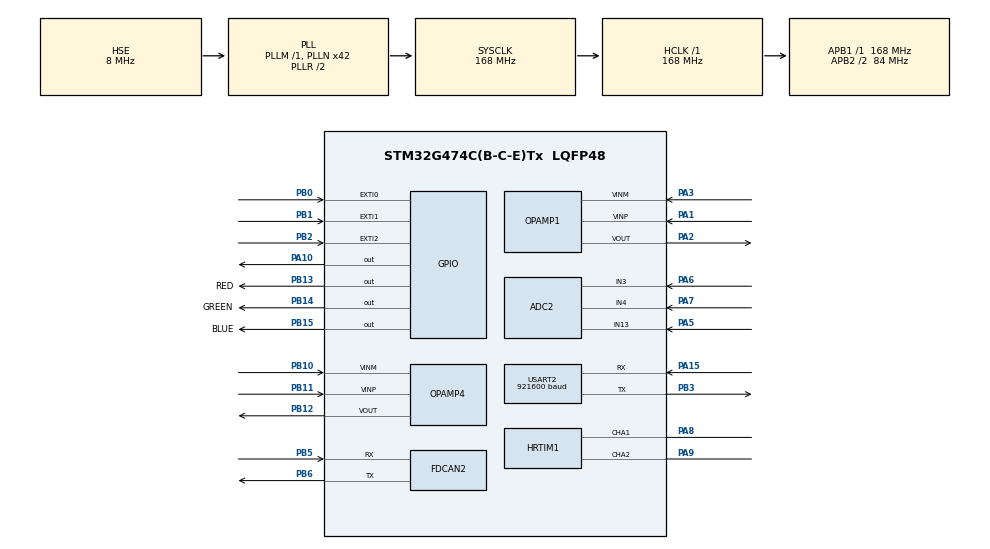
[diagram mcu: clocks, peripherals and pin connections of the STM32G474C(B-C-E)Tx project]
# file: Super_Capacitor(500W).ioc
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ADC1.Channel-1\#ChannelRegularConversion=ADC_CHANNEL_VREFINT
ADC1.Channel-2\#ChannelRegularConversion=ADC_CHANNEL_3
ADC1.Channel-4\#ChannelRegularConversion=ADC_CHANNEL_11
ADC1.DMAAccessModeView=ENABLE
ADC1.DMAContinuousRequests=ENABLE
ADC1.ExternalTrigConv=ADC_EXTERNALTRIG_HRTIM_TRG1
ADC1.Mode=ADC_DUALMODE_REGSIMULT
ADC1.NbrOfConversion=3
ADC1.NbrOfConversionFlag=1
ADC1.OffsetNumber-1\#ChannelRegularConversion=ADC_OFFSET_NONE
ADC1.OffsetNumber-2\#ChannelRegularConversion=ADC_OFFSET_NONE
ADC1.OffsetNumber-4\#ChannelRegularConversion=ADC_OFFSET_NONE
ADC1.OversamplingMode=DISABLE
ADC1.Rank-1\#ChannelRegularConversion=1
ADC1.Rank-2\#ChannelRegularConversion=2
ADC1.Rank-4\#ChannelRegularConversion=3
ADC1.SamplingTime-1\#ChannelRegularConversion=ADC_SAMPLETIME_47CYCLES_5
ADC1.SamplingTime-2\#ChannelRegularConversion=ADC_SAMPLETIME_47CYCLES_5
ADC1.SamplingTime-4\#ChannelRegularConversion=ADC_SAMPLETIME_47CYCLES_5
ADC1.master=1
ADC2.Channel-1\#ChannelRegularConversion=ADC_CHANNEL_3
ADC2.Channel-2\#ChannelRegularConversion=ADC_CHANNEL_4
ADC2.Channel-3\#ChannelRegularConversion=ADC_CHANNEL_13
ADC2.DMAAccessModeView=ENABLE
ADC2.DMAContinuousRequests=DISABLE
ADC2.Mode=ADC_DUALMODE_REGSIMULT
ADC2.NbrOfConversion=3
ADC2.NbrOfConversionFlag=1
ADC2.OffsetNumber-1\#ChannelRegularConversion=ADC_OFFSET_NONE
ADC2.OffsetNumber-2\#ChannelRegularConversion=ADC_OFFSET_NONE
ADC2.OffsetNumber-3\#ChannelRegularConversion=ADC_OFFSET_NONE
ADC2.Overrun=ADC_OVR_DATA_PRESERVED
ADC2.OversamplingMode=DISABLE
ADC2.Rank-1\#ChannelRegularConversion=1
ADC2.Rank-2\#ChannelRegularConversion=2
ADC2.Rank-3\#ChannelRegularConversion=3
ADC2.SamplingTime-1\#ChannelRegularConversion=ADC_SAMPLETIME_47CYCLES_5
ADC2.SamplingTime-2\#ChannelRegularConversion=ADC_SAMPLETIME_47CYCLES_5
ADC2.SamplingTime-3\#ChannelRegularConversion=ADC_SAMPLETIME_47CYCLES_5
Dma.ADC1.2.Direction=DMA_PERIPH_TO_MEMORY
Dma.ADC1.2.EventEnable=DISABLE
Dma.ADC1.2.Instance=DMA1_Channel3
Dma.ADC1.2.MemDataAlignment=DMA_MDATAALIGN_WORD
Dma.ADC1.2.MemInc=DMA_MINC_ENABLE
Dma.ADC1.2.Mode=DMA_CIRCULAR
Dma.ADC1.2.PeriphDataAlignment=DMA_PDATAALIGN_WORD
Dma.ADC1.2.PeriphInc=DMA_PINC_DISABLE
Dma.ADC1.2.Polarity=HAL_DMAMUX_REQ_GEN_RISING
Dma.ADC1.2.Priority=DMA_PRIORITY_VERY_HIGH
Dma.ADC1.2.RequestNumber=1
Dma.ADC1.2.SignalID=NONE
Dma.ADC1.2.SyncEnable=DISABLE
Dma.ADC1.2.SyncPolarity=HAL_DMAMUX_SYNC_NO_EVENT
Dma.ADC1.2.SyncRequestNumber=1
Dma.ADC1.2.SyncSignalID=NONE
Dma.Request0=USART2_RX
Dma.Request1=USART2_TX
Dma.Request2=ADC1
Dma.USART2_RX.0.Direction=DMA_PERIPH_TO_MEMORY
Dma.USART2_RX.0.EventEnable=DISABLE
Dma.USART2_RX.0.Instance=DMA1_Channel1
Dma.USART2_RX.0.MemDataAlignment=DMA_MDATAALIGN_BYTE
Dma.USART2_RX.0.MemInc=DMA_MINC_ENABLE
Dma.USART2_RX.0.Mode=DMA_NORMAL
Dma.USART2_RX.0.PeriphDataAlignment=DMA_PDATAALIGN_BYTE
Dma.USART2_RX.0.PeriphInc=DMA_PINC_DISABLE
Dma.USART2_RX.0.Polarity=HAL_DMAMUX_REQ_GEN_RISING
Dma.USART2_RX.0.Priority=DMA_PRIORITY_VERY_HIGH
Dma.USART2_RX.0.RequestNumber=1
Dma.USART2_RX.0.SignalID=NONE
Dma.USART2_RX.0.SyncEnable=DISABLE
Dma.USART2_RX.0.SyncPolarity=HAL_DMAMUX_SYNC_NO_EVENT
Dma.USART2_RX.0.SyncRequestNumber=1
Dma.USART2_RX.0.SyncSignalID=NONE
Dma.USART2_TX.1.Direction=DMA_MEMORY_TO_PERIPH
Dma.USART2_TX.1.EventEnable=DISABLE
Dma.USART2_TX.1.Instance=DMA1_Channel2
Dma.USART2_TX.1.MemDataAlignment=DMA_MDATAALIGN_BYTE
Dma.USART2_TX.1.MemInc=DMA_MINC_ENABLE
Dma.USART2_TX.1.Mode=DMA_NORMAL
Dma.USART2_TX.1.PeriphDataAlignment=DMA_PDATAALIGN_BYTE
Dma.USART2_TX.1.PeriphInc=DMA_PINC_DISABLE
Dma.USART2_TX.1.Polarity=HAL_DMAMUX_REQ_GEN_RISING
Dma.USART2_TX.1.Priority=DMA_PRIORITY_VERY_HIGH
Dma.USART2_TX.1.RequestNumber=1
Dma.USART2_TX.1.SignalID=NONE
Dma.USART2_TX.1.SyncEnable=DISABLE
Dma.USART2_TX.1.SyncPolarity=HAL_DMAMUX_SYNC_NO_EVENT
Dma.USART2_TX.1.SyncRequestNumber=1
Dma.USART2_TX.1.SyncSignalID=NONE
FDCAN2.CalculateBaudRateNominal=1000000
FDCAN2.CalculateTimeBitNominal=1000
FDCAN2.CalculateTimeQuantumNominal=35.714285714285715
FDCAN2.DataPrescaler=6
FDCAN2.DataSyncJumpWidth=6
FDCAN2.DataTimeSeg1=20
FDCAN2.DataTimeSeg2=7
FDCAN2.NominalPrescaler=6
FDCAN2.NominalSyncJumpWidth=6
FDCAN2.NominalTimeSeg1=20
FDCAN2.NominalTimeSeg2=7
FDCAN2.StdFiltersNbr=1
FREERTOS.Tasks01=CAN_Send_Task,24,128,StartCAN_Send_Task,As weak,NULL,Dynamic,NULL,NULL;UartRecvTask,8,256,StartUartTask,As weak,NULL,Dynamic,NULL,NULL;UartTxTask,8,256,StartUartTxTask,As weak,NULL,Dynamic,NULL,NULL;RGBTask,8,128,StartRGBTask,As weak,NULL,Dynamic,NULL,NULL
FREERTOS.configENABLE_FPU=1
FREERTOS.configGENERATE_RUN_TIME_STATS=1
FREERTOS.configTOTAL_HEAP_SIZE=6144
FREERTOS.configUSE_STATS_FORMATTING_FUNCTIONS=1
HRTIM1.ADCTrigger1_Source1=HRTIM_ADCTRIGGEREVENT13_TIMERA_CMP3
HRTIM1.ADCTrigger_Id1=HRTIM_ADCTRIGGER_1
HRTIM1.CaptureUnit1-Output_TA1TA2=__NULL
HRTIM1.CompareUnit1-Output_TA1TA2=HRTIM_COMPAREUNIT_1
HRTIM1.CompareUnit2-Output_TA1TA2=HRTIM_COMPAREUNIT_2
HRTIM1.CompareUnit3-Output_TA1TA2=HRTIM_COMPAREUNIT_3
HRTIM1.CompareUnit4-Output_TA1TA2=__NULL
HRTIM1.CompareValue1-Output_TA1TA2=0x80
HRTIM1.CompareValue2-Output_TA1TA2=53670
HRTIM1.CompareValue3-Output_TA1TA2=26880
HRTIM1.DeadTimeInsertion-Output_TA1TA2=HRTIM_TIMDEADTIMEINSERTION_ENABLED
HRTIM1.FallingLock-Output_TA1TA2=HRTIM_TIMDEADTIME_FALLINGLOCK_WRITE
HRTIM1.FallingSignLock-Output_TA1TA2=HRTIM_TIMDEADTIME_FALLINGSIGNLOCK_WRITE
HRTIM1.FallingValue-Output_TA1TA2=120
HRTIM1.GreaterCMP1_TA=HRTIM_TIMERGTCMP1_EQUAL
HRTIM1.InterleavedMode-Output_TA1TA2=HRTIM_INTERLEAVED_MODE_DISABLED
HRTIM1.NumberADCTriggerSource1=1
HRTIM1.NumberResetSource1-Output_TA1TA2=2
HRTIM1.NumberResetSource2_TA=0
HRTIM1.NumberSetSource1-Output_TA1TA2=1
HRTIM1.Periode_TA=53760
HRTIM1.PreloadEnable-Output_TA1TA2=HRTIM_PRELOAD_ENABLED
HRTIM1.PrescalerDead-Output_TA1TA2=HRTIM_TIMDEADTIME_PRESCALERRATIO_DIV8
HRTIM1.PrescalerRatio_TA=HRTIM_PRESCALERRATIO_MUL32
HRTIM1.PushPull-Output_TA1TA2=HRTIM_TIMPUSHPULLMODE_DISABLED
HRTIM1.ReSyncUpdate-Output_TA1TA2=HRTIM_TIMERESYNC_UPDATE_UNCONDITIONAL
HRTIM1.RepetitionCounter-Output_TA1TA2=0x00
HRTIM1.RepetitionUpdate-Output_TA1TA2=HRTIM_UPDATEONREPETITION_ENABLED
HRTIM1.ResetOutput1_Source1-Output_TA1TA2=HRTIM_OUTPUTRESET_TIMPER
HRTIM1.ResetOutput1_Source2-Output_TA1TA2=HRTIM_OUTPUTRESET_TIMCMP2
HRTIM1.ResetUpdate-Output_TA1TA2=HRTIM_TIMUPDATEONRESET_DISABLED
HRTIM1.RisingLock-Output_TA1TA2=HRTIM_TIMDEADTIME_RISINGLOCK_WRITE
HRTIM1.RisingSignLock-Output_TA1TA2=HRTIM_TIMDEADTIME_RISINGSIGNLOCK_WRITE
HRTIM1.RisingValue-Output_TA1TA2=120
HRTIM1.SetOutput1_Source1-Output_TA1TA2=HRTIM_OUTPUTSET_TIMCMP1
HRTIM1.SwapA=__NULL
HRTIM1.UpDownMode-Output_TA1TA2=HRTIM_TIMERUPDOWNMODE_UP
HRTIM1.postscaler1=2-1
Mcu.Family=STM32G4
Mcu.Name=STM32G474C(B-C-E)Tx
Mcu.Package=LQFP48
NVIC.DMA1_Channel1_IRQn=true\:6\:0\:true\:false\:true\:true\:false\:true\:true
NVIC.DMA1_Channel2_IRQn=true\:6\:0\:true\:false\:true\:true\:false\:true\:true
NVIC.DMA1_Channel3_IRQn=true\:5\:0\:true\:false\:true\:true\:false\:true\:true
NVIC.FDCAN2_IT0_IRQn=true\:5\:0\:false\:false\:true\:true\:true\:true\:true
NVIC.FDCAN2_IT1_IRQn=true\:5\:0\:false\:false\:true\:true\:true\:true\:true
NVIC.PriorityGroup=NVIC_PRIORITYGROUP_4
NVIC.TIM7_DAC_IRQn=true\:15\:0\:false\:false\:true\:false\:false\:true\:true
NVIC.TimeBase=TIM7_DAC_IRQn
NVIC.TimeBaseIP=TIM7
NVIC.USART2_IRQn=true\:5\:0\:false\:false\:true\:true\:true\:true\:true
PA1.Mode=Standalone
PA1.Signal=OPAMP1_VINP
PA10.GPIO_PuPd=GPIO_PULLDOWN
PA10.GPIO_Speed=GPIO_SPEED_FREQ_HIGH
PA10.Signal=GPIO_Output
PA13.Mode=Serial_Wire
PA13.Signal=SYS_JTMS-SWDIO
PA14.Mode=Serial_Wire
PA14.Signal=SYS_JTCK-SWCLK
PA15.Mode=Asynchronous
PA15.Signal=USART2_RX
PA2.Signal=SharedAnalog_PA2
PA3.Mode=Standalone
PA3.Signal=OPAMP1_VINM
PA5.Mode=IN13-Single-Ended
PA5.Signal=ADC2_IN13
PA6.Mode=IN3-Single-Ended
PA6.Signal=ADC2_IN3
PA7.Mode=IN4-Single-Ended
PA7.Signal=ADC2_IN4
PA8.GPIO_PuPd=GPIO_NOPULL
PA8.Mode=Output_TA1TA2
PA8.Signal=HRTIM1_CHA1
PA9.GPIO_PuPd=GPIO_NOPULL
PA9.Mode=Output_TA1TA2
PA9.Signal=HRTIM1_CHA2
PB0.Signal=GPXTI0
PB1.Signal=GPXTI1
PB10.Mode=Standalone
PB10.Signal=OPAMP4_VINM
PB11.Mode=Standalone
PB11.Signal=OPAMP4_VINP
PB12.Signal=SharedAnalog_PB12
PB13.GPIO_Label=RED
PB13.GPIO_PuPd=GPIO_PULLUP
PB13.GPIO_Speed=GPIO_SPEED_FREQ_MEDIUM
PB13.PinState=GPIO_PIN_SET
PB13.Signal=GPIO_Output
PB14.GPIO_Label=GREEN
PB14.GPIO_PuPd=GPIO_PULLUP
PB14.GPIO_Speed=GPIO_SPEED_FREQ_MEDIUM
PB14.PinState=GPIO_PIN_SET
PB14.Signal=GPIO_Output
PB15.GPIO_Label=BLUE
PB15.GPIO_PuPd=GPIO_PULLUP
PB15.GPIO_Speed=GPIO_SPEED_FREQ_MEDIUM
PB15.PinState=GPIO_PIN_SET
PB15.Signal=GPIO_Output
PB2.Signal=GPXTI2
PB3.Mode=Asynchronous
PB3.Signal=USART2_TX
PB5.Mode=FDCAN_Activate
PB5.Signal=FDCAN2_RX
PB6.Mode=FDCAN_Activate
PB6.Signal=FDCAN2_TX
PF0-OSC_IN.Mode=HSE-External-Oscillator
PF0-OSC_IN.Signal=RCC_OSC_IN
PF1-OSC_OUT.Mode=HSE-External-Oscillator
PF1-OSC_OUT.Signal=RCC_OSC_OUT
ProjectManager.HeapSize=0x200
ProjectManager.StackSize=0x400
ProjectManager.TargetToolchain=MDK-ARM V5.32
RCC.ADC12Freq_Value=168000000
RCC.ADC345Freq_Value=168000000
RCC.AHBFreq_Value=168000000
RCC.APB1Freq_Value=168000000
RCC.APB1TimFreq_Value=168000000
RCC.APB2CLKDivider=RCC_HCLK_DIV2
RCC.APB2Freq_Value=84000000
RCC.APB2TimFreq_Value=168000000
RCC.CK48CLockSelection=RCC_USBCLKSOURCE_HSI48
RCC.CortexFreq_Value=168000000
RCC.EXTERNAL_CLOCK_VALUE=12288000
RCC.HCLKFreq_Value=168000000
RCC.HSE_VALUE=8000000
RCC.HSI48_VALUE=48000000
RCC.HSI_VALUE=16000000
RCC.LSE_VALUE=32768
RCC.PLLN=42
RCC.PLLSourceVirtual=RCC_PLLSOURCE_HSE
RCC.SYSCLKFreq_VALUE=168000000
RCC.SYSCLKSource=RCC_SYSCLKSOURCE_PLLCLK
RCC.USBFreq_Value=48000000
RCC.VCOOutputFreq_Value=336000000
SH.SharedAnalog_PA2.0=OPAMP1_VOUT,Standalone
SH.SharedAnalog_PA2.1=ADC1_IN3,IN3-Single-Ended
SH.SharedAnalog_PB12.0=OPAMP4_VOUT,Standalone
SH.SharedAnalog_PB12.1=ADC1_IN11,IN11-Single-Ended
STMicroelectronics.X-CUBE-ALGOBUILD.1.4.0.LibraryCcDSPOoLibraryJjDSPOoLibrary=true
USART2.BaudRate=921600
USART2.VirtualMode-Asynchronous=VM_ASYNC
VP_ADC1_Vref_Input.Mode=IN-Vrefint
VP_FREERTOS_VS_CMSIS_V2.Mode=CMSIS_V2
VP_STMicroelectronics.X-CUBE-ALGOBUILD_VS_DSPOoLibraryJjLibrary_1.4.0_1.4.0.Mode=DSPOoLibraryJjLibrary
VP_SYS_VS_DBSignals.Mode=DisableDeadBatterySignals
VP_SYS_VS_tim7.Mode=TIM7
board=custom

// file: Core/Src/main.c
/* USER CODE BEGIN Header */
/**
 ******************************************************************************
 * @file           : main.c
 * @brief          : Main program body
 ******************************************************************************
 * @attention
 *
 * Copyright (c) 2026 STMicroelectronics.
 * All rights reserved.
 *
 * This software is licensed under terms that can be found in the LICENSE file
 * in the root directory of this software component.
 * If no LICENSE file comes with this software, it is provided AS-IS.
 *
 ******************************************************************************
 */
/* USER CODE END Header */
#include "main.h"
#include "cmsis_os.h"
#include "adc.h"
#include "dma.h"
#include "fdcan.h"
#include "hrtim.h"
#include "opamp.h"
#include "usart.h"
#include "gpio.h"

/* USER CODE BEGIN Includes */
#include "app_supercap.h"
#include "hal_fdcan.h"
#include "app_task_scheduler.h"
#include "app_storage.h"
#include "app_rtt.h"
#include "hal_sensor.h"
/* USER CODE END Includes */

void SystemClock_Config(void);
void MX_FREERTOS_Init(void);

int main(void)
{

  /* MCU Configuration--------------------------------------------------------*/

  /* Reset of all peripherals, Initializes the Flash interface and the Systick. */
  HAL_Init();

  /* Configure the system clock */
  SystemClock_Config();

  /* Initialize all configured peripherals */
  MX_GPIO_Init();
  MX_DMA_Init();
  MX_ADC2_Init();
  MX_HRTIM1_Init();
  MX_OPAMP1_Init();
  MX_OPAMP4_Init();
  MX_ADC1_Init();
  MX_FDCAN2_Init();
  MX_USART2_UART_Init();
  /* USER CODE BEGIN 2 */
    Hal_Sensor_Init();
    App_Supercap_Init();
    App_Storage_Init();
    App_RTT_Init();
    hal_fdcan_init();
    configureTimerForRunTimeStats();
  /* USER CODE END 2 */

  /* Init scheduler */
  osKernelInitialize();  /* Call init function for freertos objects (in cmsis_os2.c) */
  MX_FREERTOS_Init();

  /* Start scheduler */
  osKernelStart();

  /* We should never get here as control is now taken by the scheduler */

  /* Infinite loop */
    while (1) {

    }
}

void SystemClock_Config(void)
{
  RCC_OscInitTypeDef RCC_OscInitStruct = {0};
  RCC_ClkInitTypeDef RCC_ClkInitStruct = {0};

  /** Configure the main internal regulator output voltage
  */
  HAL_PWREx_ControlVoltageScaling(PWR_REGULATOR_VOLTAGE_SCALE1_BOOST);

  /** Initializes the RCC Oscillators according to the specified parameters
  * in the RCC_OscInitTypeDef structure.
  */
  RCC_OscInitStruct.OscillatorType = RCC_OSCILLATORTYPE_HSE;
  RCC_OscInitStruct.HSEState = RCC_HSE_ON;
  RCC_OscInitStruct.PLL.PLLState = RCC_PLL_ON;
  RCC_OscInitStruct.PLL.PLLSource = RCC_PLLSOURCE_HSE;
  RCC_OscInitStruct.PLL.PLLM = RCC_PLLM_DIV1;
  RCC_OscInitStruct.PLL.PLLN = 42;
  RCC_OscInitStruct.PLL.PLLP = RCC_PLLP_DIV2;
  RCC_OscInitStruct.PLL.PLLQ = RCC_PLLQ_DIV2;
  RCC_OscInitStruct.PLL.PLLR = RCC_PLLR_DIV2;
  if (HAL_RCC_OscConfig(&RCC_OscInitStruct) != HAL_OK)
  {
    Error_Handler();
  }

  /** Initializes the CPU, AHB and APB buses clocks
  */
  RCC_ClkInitStruct.ClockType = RCC_CLOCKTYPE_HCLK|RCC_CLOCKTYPE_SYSCLK
                              |RCC_CLOCKTYPE_PCLK1|RCC_CLOCKTYPE_PCLK2;
  RCC_ClkInitStruct.SYSCLKSource = RCC_SYSCLKSOURCE_PLLCLK;
  RCC_ClkInitStruct.AHBCLKDivider = RCC_SYSCLK_DIV1;
  RCC_ClkInitStruct.APB1CLKDivider = RCC_HCLK_DIV1;
  RCC_ClkInitStruct.APB2CLKDivider = RCC_HCLK_DIV2;

  if (HAL_RCC_ClockConfig(&RCC_ClkInitStruct, FLASH_LATENCY_4) != HAL_OK)
  {
    Error_Handler();
  }
}

void HAL_TIM_PeriodElapsedCallback(TIM_HandleTypeDef *htim)
{
  if (htim->Instance == TIM7)
  {
    HAL_IncTick();
  }
}

void Error_Handler(void)
{
    __disable_irq();
    while (1) {
    }
}

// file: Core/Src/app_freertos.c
/* USER CODE BEGIN Header */
/**
  ******************************************************************************
  * File Name          : app_freertos.c
  * Description        : Code for freertos applications
  ******************************************************************************
  * @attention
  *
  * Copyright (c) 2026 STMicroelectronics.
  * All rights reserved.
  *
  * This software is licensed under terms that can be found in the LICENSE file
  * in the root directory of this software component.
  * If no LICENSE file comes with this software, it is provided AS-IS.
  *
  ******************************************************************************
  */
/* USER CODE END Header */

#include "FreeRTOS.h"
#include "task.h"
#include "main.h"
#include "cmsis_os.h"

/* USER CODE BEGIN Includes */
#include "message_buffer.h"
/* USER CODE END Includes */

/* USER CODE BEGIN Variables */
MessageBufferHandle_t uartMessageBuffer;
/* USER CODE END Variables */
/* Definitions for CAN_Send_Task */
osThreadId_t CAN_Send_TaskHandle;
const osThreadAttr_t CAN_Send_Task_attributes = {
  .name = "CAN_Send_Task",
  .priority = (osPriority_t) osPriorityNormal,
  .stack_size = 128 * 4
};
/* Definitions for UartRecvTask */
osThreadId_t UartRecvTaskHandle;
const osThreadAttr_t UartRecvTask_attributes = {
  .name = "UartRecvTask",
  .priority = (osPriority_t) osPriorityLow,
  .stack_size = 256 * 4
};
/* Definitions for UartTxTask */
osThreadId_t UartTxTaskHandle;
const osThreadAttr_t UartTxTask_attributes = {
  .name = "UartTxTask",
  .priority = (osPriority_t) osPriorityLow,
  .stack_size = 256 * 4
};
/* Definitions for RGBTask */
osThreadId_t RGBTaskHandle;
const osThreadAttr_t RGBTask_attributes = {
  .name = "RGBTask",
  .priority = (osPriority_t) osPriorityLow,
  .stack_size = 128 * 4
};

void StartCAN_Send_Task(void *argument);
void StartUartTask(void *argument);
void StartUartTxTask(void *argument);
void StartRGBTask(void *argument);

void MX_FREERTOS_Init(void); /* (MISRA C 2004 rule 8.1) */

/* Hook prototypes */
void configureTimerForRunTimeStats(void);
unsigned long getRunTimeCounterValue(void);

/* USER CODE BEGIN 1 */
/* Functions needed when configGENERATE_RUN_TIME_STATS is on */
__weak void configureTimerForRunTimeStats(void)
{

}

__weak unsigned long getRunTimeCounterValue(void)
{
return 0;
}
/* USER CODE END 1 */

void MX_FREERTOS_Init(void) {

  /* Create the thread(s) */
  /* creation of CAN_Send_Task */
  CAN_Send_TaskHandle = osThreadNew(StartCAN_Send_Task, NULL, &CAN_Send_Task_attributes);

  /* creation of UartRecvTask */
  UartRecvTaskHandle = osThreadNew(StartUartTask, NULL, &UartRecvTask_attributes);

  /* creation of UartTxTask */
  UartTxTaskHandle = osThreadNew(StartUartTxTask, NULL, &UartTxTask_attributes);

  /* creation of RGBTask */
  RGBTaskHandle = osThreadNew(StartRGBTask, NULL, &RGBTask_attributes);

  /* USER CODE BEGIN RTOS_THREADS */
  /* add threads, ... */
	uartMessageBuffer = xMessageBufferCreate(128);
  /* USER CODE END RTOS_THREADS */

}

__weak void StartCAN_Send_Task(void *argument)
{
  for(;;)
  {
    osDelay(1);
  }
}

__weak void StartUartTask(void *argument)
{
  for(;;)
  {
    osDelay(1);
  }
}

__weak void StartUartTxTask(void *argument)
{
  for(;;)
  {
    osDelay(1);
  }
}

__weak void StartRGBTask(void *argument)
{
  for(;;)
  {
    osDelay(1);
  }
}
